# ATmega3208 device description
Architecture: AVR8X; Family: AVR MEGA
Registers are 8-bit, read-write, no defined reset value unless marked. A register's access mark holds for its fields unless they carry their own. Offsets are from the block's base; [hi:lo] are bit positions; {n}, {i} and the like mark numbered series; 'fields as' and 'values as' point back to an identical list.

## CLKCTRL — Clock controller
Instances: CLKCTRL 0x0060
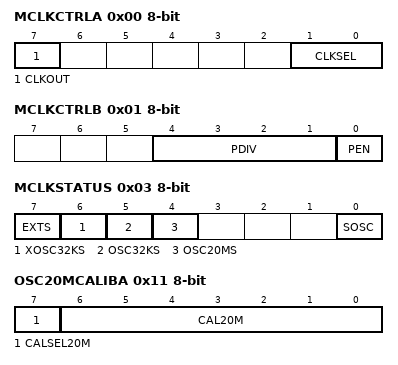
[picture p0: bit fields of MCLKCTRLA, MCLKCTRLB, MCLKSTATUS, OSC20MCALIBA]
0x00 MCLKCTRLA — MCLK Control A
  [7] CLKOUT — System clock out
  [1:0] CLKSEL — clock select
    0=OSC20M (20MHz oscillator); 1=OSCULP32K (32KHz oscillator); 2=XOSC32K (32.768kHz crystal oscillator); 3=EXTCLK (External clock)
0x01 MCLKCTRLB — MCLK Control B
  [4:1] PDIV — Prescaler division
    0=2X; 1=4X; 2=8X; 3=16X; 4=32X; 5=64X; 8=6X; 9=10X; 10=12X; 11=24X; 12=48X
  [0] PEN — Prescaler enable
0x02 MCLKLOCK
  [0] LOCKEN — lock ebable
0x03 MCLKSTATUS
  [7] EXTS — External Clock status
  [6] XOSC32KS — 32.768 kHz Crystal Oscillator status
  [5] OSC32KS — 32KHz oscillator status
  [4] OSC20MS — 20MHz oscillator status
  [0] SOSC — System Oscillator changing
0x10 OSC20MCTRLA — OSC20M Control A
  [1] RUNSTDBY — Run standby
0x11 OSC20MCALIBA — OSC20M Calibration A
  [7] CALSEL20M — Calibration freq select
  [6:0] CAL20M — Calibration
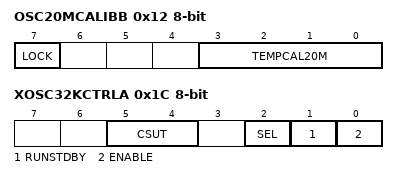
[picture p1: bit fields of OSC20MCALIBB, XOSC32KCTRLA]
0x12 OSC20MCALIBB — OSC20M Calibration B
  [7] LOCK
  [3:0] TEMPCAL20M — Oscillator temperature coefficient
0x18 OSC32KCTRLA — OSC32K Control A
  [1] RUNSTDBY — Run standby
0x19 OSC32KCALIB — OSC32K Calibration
  [5:0] CAL32K — Calibration
0x1C XOSC32KCTRLA — XOSC32K Control A
  [5:4] CSUT — Crystal startup time
    0=1K (1k cycles); 1=16K (16k cycles); 2=32K (32k cycles); 3=64K (64k cycles)
  [2] SEL — Select
  [1] RUNSTDBY — Run standby
  [0] ENABLE

## CPU
Instances: CPU 0x0030
0x04 CCP — Configuration Change Protection
  [7:0] CCP — CCP signature
    157=SPM (SPM Instruction Protection); 216=IOREG (IO Register Protection)
0x0B RAMPZ — Extended Z-pointer Register
0x0D SPL — Stack Pointer Low
0x0E SPH — Stack Pointer High
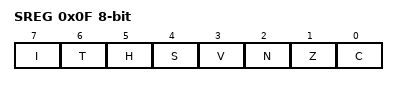
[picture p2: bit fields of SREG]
0x0F SREG — Status Register
  [7] I — Global Interrupt Enable Flag
  [6] T — Transfer Bit
  [5] H — Half Carry Flag
  [4] S — N Exclusive Or V Flag
  [3] V — Two's Complement Overflow Flag
  [2] N — Negative Flag
  [1] Z — Zero Flag
  [0] C — Carry Flag

## CPUINT — Interrupt Controller
Instances: CPUINT 0x0110
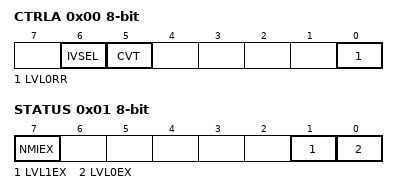
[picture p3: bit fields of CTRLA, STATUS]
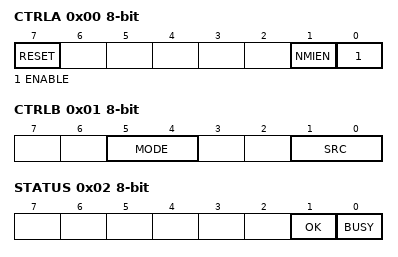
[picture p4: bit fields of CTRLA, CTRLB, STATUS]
0x00 CTRLA — Control A
  [6] IVSEL — Interrupt Vector Select
  [5] CVT — Compact Vector Table
  [0] LVL0RR — Round-robin Scheduling Enable
0x01 STATUS
  [7] NMIEX ro — Non-maskable Interrupt Executing
  [1] LVL1EX ro — Level 1 Interrupt Executing
  [0] LVL0EX ro — Level 0 Interrupt Executing
0x02 LVL0PRI — Interrupt Level 0 Priority
  [7:0] LVL0PRI — Interrupt Level Priority
0x03 LVL1VEC — Interrupt Level 1 Priority Vector
  [7:0] LVL1VEC — Interrupt Vector with High Priority

## CRCSCAN
Instances: CRCSCAN 0x0120
0x00 CTRLA — Control A
  [7] RESET — Reset CRC scan
  [1] NMIEN — Enable NMI Trigger
  [0] ENABLE — Enable CRC scan
0x01 CTRLB — Control B
  [5:4] MODE — CRC Flash Access Mode
    0=PRIORITY (Priority to flash); 2=BACKGROUND (Lowest priority to flash); 3=CONTINUOUS (Continuous checks in background)
  [1:0] SRC — CRC Source
    0=FLASH (CRC on entire flash); 1=APPLICATION (CRC on boot and appl section of flash); 2=BOOT (CRC on boot section of flash)
0x02 STATUS ro
  [1] OK — CRC Ok
  [0] BUSY — CRC Busy

## EVSYS — Event System
Instances: EVSYS 0x0180
0x00 STROBE — Channel Strobe
  [7:0] STROBE0 wo — Software event on channels
    1=EV_STROBE_CH0; 2=EV_STROBE_CH1; 4=EV_STROBE_CH2; 8=EV_STROBE_CH3; 16=EV_STROBE_CH4; 32=EV_STROBE_CH5; 64=EV_STROBE_CH6; 128=EV_STROBE_CH7
{0x10+i} CHANNEL{i} (i=0..5) — Multiplexer Channel {i}
  [7:0] GENERATOR — Generator selector
    0=OFF; 1=UPDI (Unified Program and Debug Interface); 2=OSC_TEST (Oscillator test event); 6=RTC_OVF (Real Time Counter overflow); 7=RTC_CMP (Real Time Counter compare); {v}=RTC_PIT{v-8} (Periodic Interrupt Timer output {v-8}) (v=8..11); {v}=CCL_LUT{v-16} (Configurable Custom Logic LUT{v-16}) (v=16..19); 32=AC0_OUT (Analog Comparator 0 out); 36=ADC0_COMP (ADC 0 Comparator Event); {v}=PORT0_PIN{v-64} (v=64..71); {v}=PORT1_PIN{v-72} (v=72..79); {v}=USART{v-96}_XCK (USART {v-96} Xclock) (v=96..99); 104=SPI0_SCK (SPI 0 Sclock); 128=TCA0_OVF (Timer/Counter A0 overflow); 129=TCA0_ERR (Timer/Counter A0 error); 132=TCA0_CMP0 (Timer/Counter A0 compare 0); 133=TCA0_CMP1 (Timer/Counter A0 compare 1); 134=TCA0_CMP2 (Timer/Counter A0 compare 2); 160=TCB0_CMP0 (Timer/Counter B0 compare 0); 162=TCB1_CMP0 (Timer/Counter B1 compare 0); 164=TCB2_CMP0 (Timer/Counter B2 compare 0); 166=TCB3_CMP0 (Timer/Counter B3 compare 0)
{0x20+2i} USERCCLLUT{i}A (i=0..3) — User CCL LUT{i} Event A
  [7:0] CHANNEL — Channel selector
    0=OFF; {v}=Connect user to event channel {v-1} (v=1..6)
{0x21+2i} USERCCLLUT{i}B (i=0..3) — User CCL LUT{i} Event B
  fields as USERCCLLUT0A
0x28 USERADC0
  fields as USERCCLLUT0A
0x29 USEREVOUTA — User EVOUT Port A
  fields as USERCCLLUT0A
0x2A USEREVOUTB — User EVOUT Port B
  fields as USERCCLLUT0A
0x2B USEREVOUTC — User EVOUT Port C
  fields as USERCCLLUT0A
0x2C USEREVOUTD — User EVOUT Port D
  fields as USERCCLLUT0A
0x2D USEREVOUTE — User EVOUT Port E
  fields as USERCCLLUT0A
0x2E USEREVOUTF — User EVOUT Port F
  fields as USERCCLLUT0A
{0x2F+i} USERUSART{i} (i=0..3)
  fields as USERCCLLUT0A
0x33 USERTCA0
  fields as USERCCLLUT0A
{0x34+i} USERTCB{i} (i=0..3)
  fields as USERCCLLUT0A
